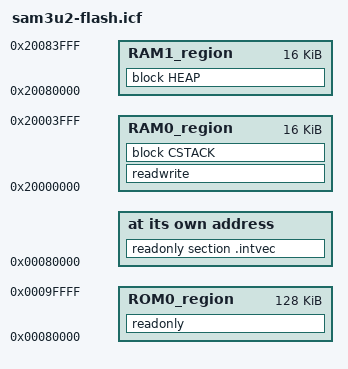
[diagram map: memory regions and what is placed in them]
/*!
@file sam3u2-flash.icf
@brief Linker file for EiE Cortex-M3 development boards running the EiE firmware 

Do not use the IAR ICF linker file editor as the tags have been removed.
*/

/*-Specials-*/
define symbol __ICFEDIT_intvec_start__ = 0x00080000; /*Add for CMSIS*/

/*-Memory Regions-*/
define symbol __ICFEDIT_region_RAM0_start__  = 0x20000000;
define symbol __ICFEDIT_region_RAM0_end__    = 0x20003FFF;
define symbol __ICFEDIT_region_RAM1_start__  = 0x20080000;
define symbol __ICFEDIT_region_RAM1_end__    = 0x20083FFF;
define symbol __ICFEDIT_region_ROM0_start__  = 0x00080000;
define symbol __ICFEDIT_region_ROM0_end__    = 0x0009FFFF;

/*-Sizes-*/
define symbol __ICFEDIT_size_cstack__        = 0x1000;
define symbol __ICFEDIT_size_heap__          = 0x4000;
define memory mem with size   = 4G;

/*-Exports and defines for RAM vector table NOT USED  -*/
/*define symbol __ICFEDIT_region_RAM_VECT_start__ = __ICFEDIT_region_RAM0_start__;*/ /*Referenced for CMSIS*/
/*define symbol __ICFEDIT_size_vectors__          = 0x100;*/ /*Referenced for CMSIS*/

/*export symbol __ICFEDIT_region_RAM_VECT_start__;*/
/*define region RAM_VECT_region = mem:[from __ICFEDIT_region_RAM_VECT_start__ size __ICFEDIT_size_vectors__];*/ /*Referenced for CMSIS*/
/*define region RAM0_region     = mem:[from __ICFEDIT_region_RAM0_start__+__ICFEDIT_size_vectors__ to __ICFEDIT_region_RAM0_end__];*/ /*Referenced for CMSIS*/
/*define region RAM_region      = mem:[from __ICFEDIT_region_RAM0_start__+__ICFEDIT_size_vectors__ to __ICFEDIT_region_RAM0_end__] |
                                  mem:[from __ICFEDIT_region_RAM1_start__ to __ICFEDIT_region_RAM1_end__];*/ /*Referenced for CMSIS*/
/*define block RamVect   with alignment = 8, size = __ICFEDIT_size_vectors__  { };*/

/*-Exports and defines for ROM vector table -*/
export symbol __ICFEDIT_intvec_start__; /*Add for CMSIS*/
define region RAM0_region     = mem:[from __ICFEDIT_region_RAM0_start__ to __ICFEDIT_region_RAM0_end__];
define region RAM1_region     = mem:[from __ICFEDIT_region_RAM1_start__ to __ICFEDIT_region_RAM1_end__];
define region ROM0_region     = mem:[from __ICFEDIT_region_ROM0_start__ to __ICFEDIT_region_ROM0_end__];

define block CSTACK    with alignment = 8, size = __ICFEDIT_size_cstack__   { };
define block HEAP      with alignment = 8, size = __ICFEDIT_size_heap__     { };

initialize by copy { readwrite };
do not initialize  { section .noinit };

/*place at start of ROM0_region { readonly section .intvec };*/ /*Referenced for CMSIS*/
/*place in RAM_VECT_region      { block RamVect };*/ /*Referenced for CMSIS*/
place at address mem:__ICFEDIT_intvec_start__ { readonly section .intvec }; /*Add for CMSIS*/
place in ROM0_region          { readonly };
place in RAM0_region          { readwrite, block CSTACK };
place in RAM1_region          { block HEAP }; /* for nandflash*/
